# nrf54h20_enga_application register map
Vendor: Nordic Semiconductor; Series: nRF54h; File version: 1
CPU: CM33 r0p4, little endian, MPU, FPU, 3 interrupt priority bits, 480 interrupts, 4 SAU regions
Registers are 32-bit, read-write, reset 0x0 unless marked. A register's access mark holds for its fields unless they carry their own. Offsets are from the block's base; [hi:lo] are bit positions.

## GLOBAL_ETB_NS — Embedded Trace Buffer
Base 0xBF044000
0x04 RDP ro — ETB RAM Depth Register
  [31:0] ETB_RAM_DEPTH — Defines the depth, in words, of the trace RAM.
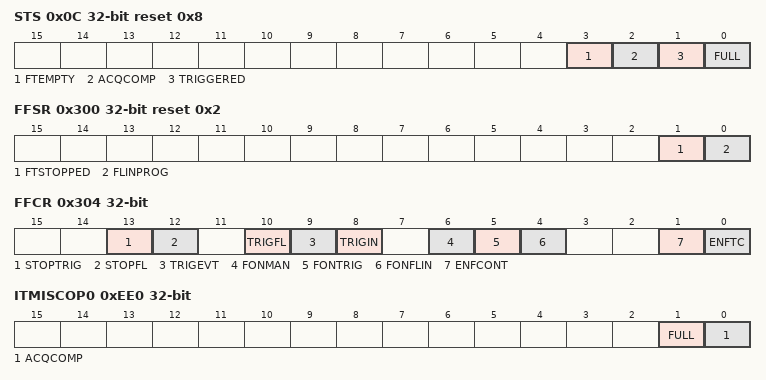
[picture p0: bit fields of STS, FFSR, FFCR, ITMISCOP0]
0x0C STS ro reset 0x8 — ETB Status Register
  [3] FTEMPTY — Formatter pipeline empty. All data stored to RAM.
  [2] ACQCOMP — The acquisition complete flag indicates that capture has been completed when the formatter stops because of any of the methods defined in the Formatter and Flush Control Register, or TraceCaptEn = 0. This also results in FtStopped in the Formatter and Flush Status Register going HIGH.
  [1] TRIGGERED — The Triggered bit is set when a trigger has been observed. This does not indicate that a trigger has been embedded in the trace data by the formatter, but is determined by the programming of the Formatter and Flush Control Register.
  [0] FULL — RAM Full. The flag indicates when the RAM write pointer has wrapped around.
0x10 RRD ro — ETB RAM Read Data Register
  [31:0] RAM_READ_DATA — Data read from the ETB Trace RAM.
0x14 RRP — ETB RAM Read Pointer Register
  [9:0] RAM_READ_POINTER — Sets the read pointer used to read entries from the Trace RAM over the APB interface.
0x18 RWP — ETB RAM Write Pointer Register
  [9:0] RAM_WRITE_POINTER — Sets the write pointer used to write entries from the CoreSight bus into the Trace RAM.
0x1C TRG — ETB Trigger Counter Register
  [9:0] TRIGGER_COUNTER — The counter is used as follows:Trace after - The counter is set to a large value, slightly less than the number of entries in the RAM. Trace before - The counter is set to a small value. Trace about - The counter is set to half the depth of the Trace RAM. This register must not be written to when trace capture is enabled (FtStopped=0, TraceCaptEn=1). If a write is attempted, the register is not updated. A read access is permitted with trace capture enabled.
0x20 CTL — ETB Control Register
  [0] TRACECAPTEN — ETB Trace Capture Enable. This is the master enable bit forcing FtStopped HIGH when TraceCaptEn is LOW. When capture is disabled, any remaining data in the ATB formatter is stored to RAM. When all data is stored the formatter outputs FtStopped. Capture is fully disabled, or complete, when FtStopped goes HIGH. See ETB Formatter and Flush Status Register, FFSR, 0x300.
0x24 RWD — ETB RAM Write Data Register
  [31:0] RAM_WRITE_DATA — Data written to the ETB Trace RAM. When trace capture is disabled, the contents of this register are placed into the ETB Trace RAM when this register is written to. Writing to this register increments the RAM Write Pointer Register. If trace capture is enabled, and this register is accessed, then a read from this register outputs 0xFFFFFFFF. Reads of this register never increment the RAM Write Pointer Register. A constant stream of 1s being output corresponds to a synchronization output from the ETB. If a write access is attempted, the data is not written into Trace RAM.
0x300 FFSR ro reset 0x2 — ETB Formatter and Flush Status Register
  [1] FTSTOPPED — Formatter stopped. The formatter has received a stop request signal and all trace data and post-amble has been output. Any more trace data on the ATB interface is ignored and atreadys goes HIGH.
  [0] FLINPROG — Flush In Progress. This is an indication of the current state of afvalids.
0x304 FFCR — ETB Formatter and Flush Control Register
  [13] STOPTRIG — Stop the formatter after a Trigger Event is observed. Reset to disabled (zero).
  [12] STOPFL — This forces the FIFO to drain off any part-completed packets. Setting this bit enables this function but this is clear on reset (disabled).
  [10] TRIGFL — Indicates a trigger on Flush completion (afreadys being returned).
  [9] TRIGEVT — Indicate a trigger on a Trigger Event.
  [8] TRIGIN — Indicate a trigger on trigin being asserted.
  [6] FONMAN — Setting this bit causes a flush to be generated. This is cleared when this flush has been serviced. This bit is clear on reset.
  [5] FONTRIG — Generate flush using Trigger event. Set this bit to cause a flush of data in the system when a Trigger Event occurs. This bit is clear on reset. A Trigger Event is defined as when the Trigger counter reaches zero (where fitted) or, in the case of the trigger counter being zero (or not fitted), when trigin is HIGH.
  [4] FONFLIN — Set this bit to enable use of the flushin connection. This is clear on reset.
  [1] ENFCONT — Continuous mode in the ETB corresponds to normal mode with the embedding of triggers. Can only be changed when FtStopped is HIGH. This bit is clear on reset.
  [0] ENFTC — Do not embed Triggers into the formatted stream. Trace disable cycles and triggers are indicated by TRACECTL, where fitted. Can only be changed when FtStopped is HIGH. This bit is clear on reset.
0xEE0 ITMISCOP0 wo — Integration Test Miscellaneous Output Register 0
  [1] FULL — Set the value of full output port.
  [0] ACQCOMP — Set the value of acqcomp.
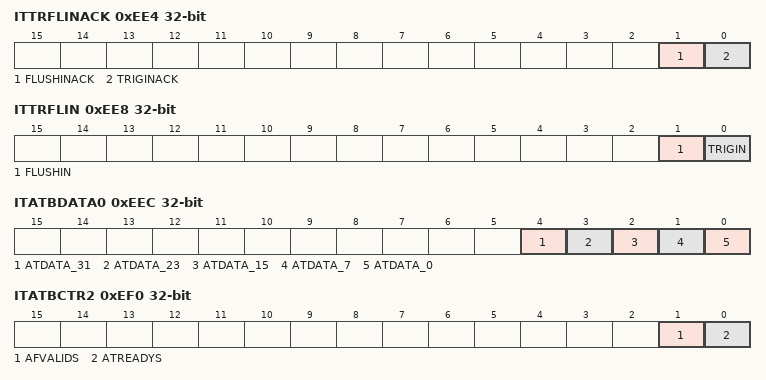
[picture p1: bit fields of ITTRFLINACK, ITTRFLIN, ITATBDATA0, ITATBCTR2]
0xEE4 ITTRFLINACK wo — Integration Test Trigger In and Flush In Acknowledge Register
  [1] FLUSHINACK — Set the value of flushinack.
  [0] TRIGINACK — Set the value of triginack.
0xEE8 ITTRFLIN ro — Integration Test Trigger In and Flush In Register
  [1] FLUSHIN — Read the value of flushin.
  [0] TRIGIN — Read the value of trigin.
0xEEC ITATBDATA0 ro — Integration Test ATB Data Register 0
  [4] ATDATA_31 — Read the value of atdatas[31].
  [3] ATDATA_23 — Read the value of atdatas[23].
  [2] ATDATA_15 — Read the value of atdatas[15].
  [1] ATDATA_7 — Read the value of atdatas[7].
  [0] ATDATA_0 — Read the value of atdatas[0].
0xEF0 ITATBCTR2 wo — Integration Test ATB Control Register 2
  [1] AFVALIDS — Set the value of afvalids.
  [0] ATREADYS — Set the value of atreadys.
0xEF4 ITATBCTR1 ro — Integration Test ATB Control Register 1
  [6:0] ATID — Read the value of atids.
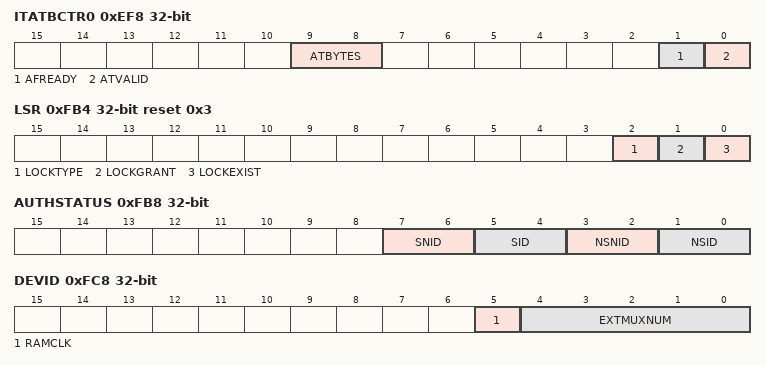
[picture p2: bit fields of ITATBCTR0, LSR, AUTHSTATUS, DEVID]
0xEF8 ITATBCTR0 ro — Integration Test ATB Control Register 0
  [9:8] ATBYTES — Read the value of atbytess.
  [1] AFREADY — Read the value of afreadys.
  [0] ATVALID — Read the value of atvalids.
0xF00 ITCTRL — Integration Mode Control Register
  [0] INTEGRATION_MODE — Allows the component to switch from functional mode to integration mode or back.
0xFA0 CLAIMSET reset 0xF — Claim Tag Set Register
  [3:0] CLAIMSET — This claim tag bit is implemented
0xFA4 CLAIMCLR — Claim Tag Clear Register
  [3:0] CLAIMCLR — The value present reflects the current setting of the Claim Tag.
0xFB0 LAR wo — Lock Access Register
  [31:0] ACCESS_W — A write of 0xC5ACCE55 enables further write access to this device. A write of any value other than 0xC5ACCE55 will have the affect of removing write access.
0xFB4 LSR ro reset 0x3 — Lock Status Register
  [2] LOCKTYPE — Indicates if the Lock Access Register (0xFB0) is implemented as 8-bit or 32-bit
  [1] LOCKGRANT — Returns the current status of the Lock. This bit reads as 0 when read from an external debugger (paddrdbg31 = 1) since external debugger accesses are not subject to Lock Registers.
  [0] LOCKEXIST — Indicates that a lock control mechanism exists for this device. This bit reads as 0 when read from an external debugger (paddrdbg31 = 1) since external debugger accesses are not subject to Lock Registers.
0xFB8 AUTHSTATUS ro — Authentication Status Register
  [7:6] SNID — Indicates the security level for secure non-invasive debug
  [5:4] SID — Indicates the security level for secure invasive debug
  [3:2] NSNID — Indicates the security level for non-secure non-invasive debug
  [1:0] NSID — Indicates the security level for non-secure invasive debug
0xFC8 DEVID ro — Device Configuration Register
  [5] RAMCLK — This bit returns 0 on reads indicating that the ETB RAM operates synchronously to atclk.
  [4:0] EXTMUXNUM — When non-zero this value indicates the type/number of ATB multiplexing present on the input to the ATB.
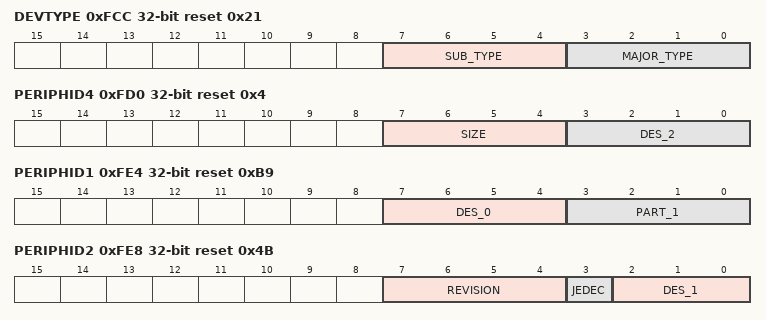
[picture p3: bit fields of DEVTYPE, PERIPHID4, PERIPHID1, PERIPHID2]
0xFCC DEVTYPE ro reset 0x21 — Device Type Identifier Register
  [7:4] SUB_TYPE — Sub-classification within the major category
  [3:0] MAJOR_TYPE — Major classification grouping for this debug/trace component
0xFD0 PERIPHID4 ro reset 0x4 — Peripheral ID4 Register
  [7:4] SIZE — This is a 4-bit value that indicates the total contiguous size of the memory window used by this component in powers of 2 from the standard 4KB. If a component only requires the standard 4KB then this should read as 0x0, 4KB only, for 8KB set to 0x1, 16KB == 0x2, 32KB == 0x3, and so on.
  [3:0] DES_2 — JEDEC continuation code indicating the designer of the component (along with the identity code)
0xFE0 PERIPHID0 ro reset 0x7 — Peripheral ID0 Register
  [7:0] PART_0 — Bits [7:0] of the component's part number. This is selected by the designer of the component.
0xFE4 PERIPHID1 ro reset 0xB9 — Peripheral ID1 Register
  [7:4] DES_0 — Bits 3:0 of the JEDEC identity code indicating the designer of the component (along with the continuation code)
  [3:0] PART_1 — Bits [11:8] of the component's part number. This is selected by the designer of the component.
0xFE8 PERIPHID2 ro reset 0x4B — Peripheral ID2 Register
  [7:4] REVISION — The Revision field is an incremental value starting at 0x0 for the first design of this component. This only increases by 1 for both major and minor revisions and is simply used as a look-up to establish the exact major/minor revision.
  [3] JEDEC — Always set. Indicates that a JEDEC assigned value is used
  [2:0] DES_1 — Bits 6:4 of the JEDEC identity code indicating the designer of the component (along with the continuation code)
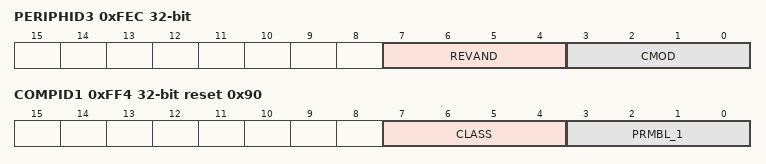
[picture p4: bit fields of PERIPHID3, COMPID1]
0xFEC PERIPHID3 ro — Peripheral ID3 Register
  [7:4] REVAND — This field indicates minor errata fixes specific to this design, for example metal fixes after implementation. In most cases this field is zero. It is recommended that component designers ensure this field can be changed by a metal fix if required, for example by driving it from registers that reset to zero.
  [3:0] CMOD — Where the component is reusable IP, this value indicates if the customer has modified the behavior of the component. In most cases this field is zero.
0xFF0 COMPID0 ro reset 0xD — Component ID0 Register
  [7:0] PRMBL_0 — Contains bits [7:0] of the component identification
0xFF4 COMPID1 ro reset 0x90 — Component ID1 Register
  [7:4] CLASS — Class of the component. E. g. ROM table, CoreSight component etc. Constitutes bits [15:12] of the component identification.
  [3:0] PRMBL_1 — Contains bits [11:8] of the component identification
0xFF8 COMPID2 ro reset 0x5 — Component ID2 Register
  [7:0] PRMBL_2 — Contains bits [23:16] of the component identification
0xFFC COMPID3 ro reset 0xB1 — Component ID3 Register
  [7:0] PRMBL_3 — Contains bits [31:24] of the component identification
